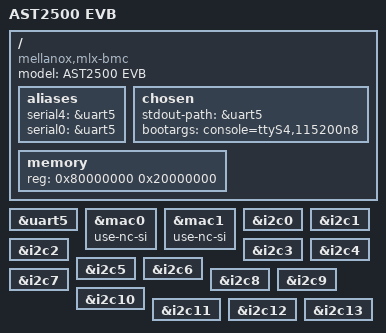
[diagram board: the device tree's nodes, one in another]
/dts-v1/;

#include "aspeed-g5-mlx.dtsi"

/ {
	model = "AST2500 EVB";
	compatible = "mellanox,mlx-bmc", "aspeed,ast2500-evb", "aspeed,ast2500";

	aliases {
		serial4 = &uart5;
	};

        aliases {
                serial0 = &uart5;
        };

	chosen {
		stdout-path = &uart5;
		bootargs = "console=ttyS4,115200n8";
	};

	memory {
		reg = <0x80000000 0x20000000>;
	};
};

&uart5 {
	status = "okay";
};

&mac0 {
        status = "okay";
        use-nc-si;
};

&mac1 {
        status = "okay";
        use-nc-si;
};

&i2c0 {
	status = "okay";
};

&i2c1 {
	status = "okay";
};

&i2c2 {
	status = "okay";
};

&i2c3 {
	status = "okay";
};

&i2c4 {
	status = "okay";
};

&i2c5 {
	status = "okay";
};

&i2c6 {
	status = "okay";
};

&i2c7 {
	status = "okay";
};

&i2c8 {
	status = "okay";
};

&i2c9 {
	status = "okay";
};

&i2c10 {
	status = "okay";
};

&i2c11 {
	status = "okay";
};

&i2c12 {
	status = "okay";
};

&i2c13 {
	status = "okay";
};
